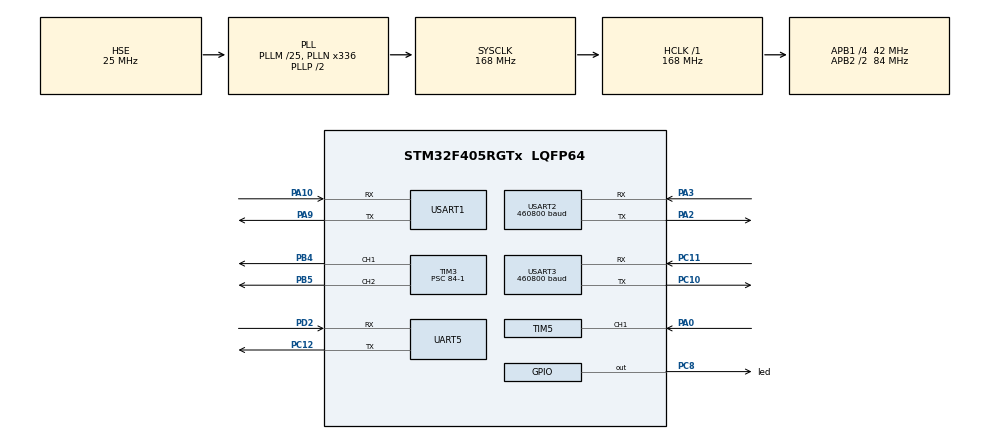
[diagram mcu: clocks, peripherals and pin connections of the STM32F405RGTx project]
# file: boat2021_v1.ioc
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FREERTOS.Tasks01=defaultTask,24,128,StartDefaultTask,Default,NULL,Dynamic,NULL,NULL;myTask02,8,256,StartTask02,As external,NULL,Dynamic,NULL,NULL;myTask03,8,256,StartTask03,As external,NULL,Dynamic,NULL,NULL
Mcu.Family=STM32F4
Mcu.Name=STM32F405RGTx
Mcu.Package=LQFP64
NVIC.PriorityGroup=NVIC_PRIORITYGROUP_4
NVIC.TIM1_UP_TIM10_IRQn=true\:0\:0\:false\:false\:true\:false\:false\:true
NVIC.TIM5_IRQn=true\:5\:0\:false\:false\:true\:true\:true\:true
NVIC.TimeBase=TIM1_UP_TIM10_IRQn
NVIC.TimeBaseIP=TIM1
NVIC.UART5_IRQn=true\:5\:0\:false\:false\:true\:true\:true\:true
NVIC.USART1_IRQn=true\:5\:0\:false\:false\:true\:true\:true\:true
NVIC.USART2_IRQn=true\:5\:0\:false\:false\:true\:true\:true\:true
NVIC.USART3_IRQn=true\:5\:0\:false\:false\:true\:true\:true\:true
PA0-WKUP.Signal=S_TIM5_CH1
PA10.GPIO_PuPd=GPIO_PULLUP
PA10.Mode=Asynchronous
PA10.Signal=USART1_RX
PA13.Mode=Serial_Wire
PA13.Signal=SYS_JTMS-SWDIO
PA14.Mode=Serial_Wire
PA14.Signal=SYS_JTCK-SWCLK
PA2.Mode=Asynchronous
PA2.Signal=USART2_TX
PA3.Mode=Asynchronous
PA3.Signal=USART2_RX
PA9.GPIO_PuPd=GPIO_PULLUP
PA9.Mode=Asynchronous
PA9.Signal=USART1_TX
PB4.Signal=S_TIM3_CH1
PB5.Signal=S_TIM3_CH2
PC10.Mode=Asynchronous
PC10.Signal=USART3_TX
PC11.Mode=Asynchronous
PC11.Signal=USART3_RX
PC12.Mode=Asynchronous
PC12.Signal=UART5_TX
PC8.GPIO_Label=led
PC8.Signal=GPIO_Output
PD2.Mode=Asynchronous
PD2.Signal=UART5_RX
PH0-OSC_IN.Mode=HSE-External-Oscillator
PH0-OSC_IN.Signal=RCC_OSC_IN
PH1-OSC_OUT.Mode=HSE-External-Oscillator
PH1-OSC_OUT.Signal=RCC_OSC_OUT
ProjectManager.HeapSize=0x200
ProjectManager.StackSize=0x400
ProjectManager.TargetToolchain=MDK-ARM V5
RCC.48MHZClocksFreq_Value=84000000
RCC.AHBFreq_Value=168000000
RCC.APB1CLKDivider=RCC_HCLK_DIV4
RCC.APB1Freq_Value=42000000
RCC.APB1TimFreq_Value=84000000
RCC.APB2CLKDivider=RCC_HCLK_DIV2
RCC.APB2Freq_Value=84000000
RCC.APB2TimFreq_Value=168000000
RCC.CortexFreq_Value=168000000
RCC.HCLKFreq_Value=168000000
RCC.HSE_VALUE=25000000
RCC.HSI_VALUE=16000000
RCC.LSE_VALUE=32768
RCC.PLLM=25
RCC.PLLN=336
RCC.PLLSourceVirtual=RCC_PLLSOURCE_HSE
RCC.SYSCLKFreq_VALUE=168000000
RCC.SYSCLKSource=RCC_SYSCLKSOURCE_PLLCLK
RCC.VCOOutputFreq_Value=336000000
SH.S_TIM3_CH1.0=TIM3_CH1,PWM Generation1 CH1
SH.S_TIM3_CH2.0=TIM3_CH2,PWM Generation2 CH2
SH.S_TIM5_CH1.0=TIM5_CH1,Input_Capture1_from_TI1
TIM3.Channel-PWM\ Generation1\ CH1=TIM_CHANNEL_1
TIM3.Channel-PWM\ Generation2\ CH2=TIM_CHANNEL_2
TIM3.Period=20000-1
TIM3.Prescaler=84-1
TIM3.Pulse-PWM\ Generation1\ CH1=1500-1
TIM3.Pulse-PWM\ Generation2\ CH2=1500-1
TIM5.Channel-Input_Capture1_from_TI1=TIM_CHANNEL_1
TIM5.Period=0xFFFF
TIM5.Prescaler=84-1
UART5.VirtualMode=Asynchronous
USART1.VirtualMode=VM_ASYNC
USART2.BaudRate=460800
USART2.VirtualMode=VM_ASYNC
USART3.BaudRate=460800
USART3.VirtualMode=VM_ASYNC
VP_FREERTOS_VS_CMSIS_V2.Mode=CMSIS_V2
VP_SYS_VS_tim1.Mode=TIM1
board=custom

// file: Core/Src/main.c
/* USER CODE BEGIN Header */
/**
  ******************************************************************************
  * @file           : main.c
  * @brief          : Main program body
  ******************************************************************************
  * @attention
  *
  * <h2><center>&copy; Copyright (c) 2021 STMicroelectronics.
  * All rights reserved.</center></h2>
  *
  * This software component is licensed by ST under Ultimate Liberty license
  * SLA0044, the "License"; You may not use this file except in compliance with
  * the License. You may obtain a copy of the License at:
  *                             www.st.com/SLA0044
  *
  ******************************************************************************
  */
/* USER CODE END Header */
#include "main.h"
#include "cmsis_os.h"
#include "tim.h"
#include "usart.h"
#include "gpio.h"

void SystemClock_Config(void);
void MX_FREERTOS_Init(void);

/* USER CODE BEGIN 0 */
#include "../../MDK-ARM/pc.h"
/* USER CODE END 0 */

int main(void)
{

  /* MCU Configuration--------------------------------------------------------*/

  /* Reset of all peripherals, Initializes the Flash interface and the Systick. */
  HAL_Init();

  /* Configure the system clock */
  SystemClock_Config();

  /* Initialize all configured peripherals */
  MX_GPIO_Init();
  MX_TIM3_Init();
  MX_TIM5_Init();
  MX_UART5_Init();
  MX_USART1_UART_Init();
  MX_USART2_UART_Init();
  MX_USART3_UART_Init();

  /* Init scheduler */
  osKernelInitialize();  /* Call init function for freertos objects (in freertos.c) */
  MX_FREERTOS_Init();
  /* Start scheduler */
  osKernelStart();

  /* We should never get here as control is now taken by the scheduler */
  /* Infinite loop */
  while (1)
  {

  }
}

void SystemClock_Config(void)
{
  RCC_OscInitTypeDef RCC_OscInitStruct = {0};
  RCC_ClkInitTypeDef RCC_ClkInitStruct = {0};

  /** Configure the main internal regulator output voltage
  */
  __HAL_RCC_PWR_CLK_ENABLE();
  __HAL_PWR_VOLTAGESCALING_CONFIG(PWR_REGULATOR_VOLTAGE_SCALE1);
  /** Initializes the RCC Oscillators according to the specified parameters
  * in the RCC_OscInitTypeDef structure.
  */
  RCC_OscInitStruct.OscillatorType = RCC_OSCILLATORTYPE_HSE;
  RCC_OscInitStruct.HSEState = RCC_HSE_ON;
  RCC_OscInitStruct.PLL.PLLState = RCC_PLL_ON;
  RCC_OscInitStruct.PLL.PLLSource = RCC_PLLSOURCE_HSE;
  RCC_OscInitStruct.PLL.PLLM = 25;
  RCC_OscInitStruct.PLL.PLLN = 336;
  RCC_OscInitStruct.PLL.PLLP = RCC_PLLP_DIV2;
  RCC_OscInitStruct.PLL.PLLQ = 4;
  if (HAL_RCC_OscConfig(&RCC_OscInitStruct) != HAL_OK)
  {
    Error_Handler();
  }
  /** Initializes the CPU, AHB and APB buses clocks
  */
  RCC_ClkInitStruct.ClockType = RCC_CLOCKTYPE_HCLK|RCC_CLOCKTYPE_SYSCLK
                              |RCC_CLOCKTYPE_PCLK1|RCC_CLOCKTYPE_PCLK2;
  RCC_ClkInitStruct.SYSCLKSource = RCC_SYSCLKSOURCE_PLLCLK;
  RCC_ClkInitStruct.AHBCLKDivider = RCC_SYSCLK_DIV1;
  RCC_ClkInitStruct.APB1CLKDivider = RCC_HCLK_DIV4;
  RCC_ClkInitStruct.APB2CLKDivider = RCC_HCLK_DIV2;

  if (HAL_RCC_ClockConfig(&RCC_ClkInitStruct, FLASH_LATENCY_5) != HAL_OK)
  {
    Error_Handler();
  }
}

 /**
  * @brief  Period elapsed callback in non blocking mode
  * @note   This function is called  when TIM1 interrupt took place, inside
  * HAL_TIM_IRQHandler(). It makes a direct call to HAL_IncTick() to increment
  * a global variable "uwTick" used as application time base.
  * @param  htim : TIM handle
  * @retval None
  */
void HAL_TIM_PeriodElapsedCallback(TIM_HandleTypeDef *htim)
{
  if (htim->Instance == TIM1) {
    HAL_IncTick();
  }
  /* USER CODE BEGIN Callback 1 */
 if (htim->Instance == TIM1) {
		pc_time_callback(&pcHandle);
	}
  /* USER CODE END Callback 1 */
}

void Error_Handler(void)
{
  __disable_irq();
  while (1)
  {
  }
}

/************************ (C) COPYRIGHT STMicroelectronics *****END OF FILE****/

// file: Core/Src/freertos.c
/* USER CODE BEGIN Header */
/**
  ******************************************************************************
  * File Name          : freertos.c
  * Description        : Code for freertos applications
  ******************************************************************************
  * @attention
  *
  * <h2><center>&copy; Copyright (c) 2021 STMicroelectronics.
  * All rights reserved.</center></h2>
  *
  * This software component is licensed by ST under Ultimate Liberty license
  * SLA0044, the "License"; You may not use this file except in compliance with
  * the License. You may obtain a copy of the License at:
  *                             www.st.com/SLA0044
  *
  ******************************************************************************
  */
/* USER CODE END Header */

#include "FreeRTOS.h"
#include "task.h"
#include "main.h"
#include "cmsis_os.h"

/* Definitions for defaultTask */
osThreadId_t defaultTaskHandle;
const osThreadAttr_t defaultTask_attributes = {
  .name = "defaultTask",
  .priority = (osPriority_t) osPriorityNormal,
  .stack_size = 128 * 4
};
/* Definitions for myTask02 */
osThreadId_t myTask02Handle;
const osThreadAttr_t myTask02_attributes = {
  .name = "myTask02",
  .priority = (osPriority_t) osPriorityLow,
  .stack_size = 256 * 4
};
/* Definitions for myTask03 */
osThreadId_t myTask03Handle;
const osThreadAttr_t myTask03_attributes = {
  .name = "myTask03",
  .priority = (osPriority_t) osPriorityLow,
  .stack_size = 256 * 4
};

void StartDefaultTask(void *argument);
extern void StartTask02(void *argument);
extern void StartTask03(void *argument);

void MX_FREERTOS_Init(void); /* (MISRA C 2004 rule 8.1) */

void MX_FREERTOS_Init(void) {

  /* Create the thread(s) */
  /* creation of defaultTask */
  defaultTaskHandle = osThreadNew(StartDefaultTask, NULL, &defaultTask_attributes);

  /* creation of myTask02 */
  myTask02Handle = osThreadNew(StartTask02, NULL, &myTask02_attributes);

  /* creation of myTask03 */
  myTask03Handle = osThreadNew(StartTask03, NULL, &myTask03_attributes);

}

void StartDefaultTask(void *argument)
{
  for(;;)
  {
    osDelay(1);
  }
}

/************************ (C) COPYRIGHT STMicroelectronics *****END OF FILE****/
